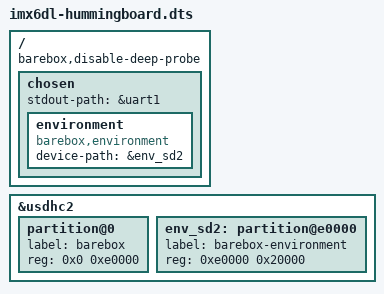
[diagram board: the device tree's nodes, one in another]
/*
 * Copyright (C) 2013 Russell King
 *
 * The code contained herein is licensed under the GNU General Public
 * License version 2.
 */

#include <arm/nxp/imx/imx6dl-hummingboard.dts>
#include "imx6qdl.dtsi"

/ {
	barebox,disable-deep-probe;

	chosen {
		stdout-path = &uart1;

		environment {
			compatible = "barebox,environment";
			device-path = &env_sd2;
		};
	};
};

&usdhc2 {
	#address-cells = <1>;
	#size-cells = <1>;

	partition@0 {
		label = "barebox";
		reg = <0x0 0xe0000>;
	};

	env_sd2: partition@e0000 {
		label = "barebox-environment";
		reg = <0xe0000 0x20000>;
	};
};
